AUTOSAR XML (schema 4-0-3)
standard types defined: UInt16
package /AUTOSAR_Platform/DataConstrs
  range DC_UInt16: raw 0..65535
package /PATAC/MSM/ComponentTypes
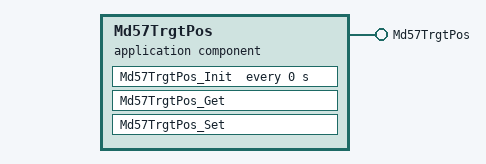
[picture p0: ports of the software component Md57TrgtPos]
  application sw component type Md57TrgtPos
    provide port Md57TrgtPos: provided-com-specs=[{operation=Get, queue-length=1}, {operation=Set, queue-length=1}], provided-interface=Md57TrgtPos
    behavior Md57TrgtPos_InternalBehavior
      operation invoked event OIT_Md57TrgtPos_Get_Md57TrgtPos_Get: start-on-event=Md57TrgtPos_Get, operation=Md57TrgtPos.Get
      timing event Md57TrgtPos_InitEvent: start-on-event=Md57TrgtPos_Init, period=0
      operation invoked event OIT_Md57TrgtPos_Set_Md57TrgtPos_Set: start-on-event=Md57TrgtPos_Set, operation=Md57TrgtPos.Set
      runnable Md57TrgtPos_Get
      runnable Md57TrgtPos_Init
      runnable Md57TrgtPos_Set
  swc implementation Md57TrgtPos_Implementation: behavior=Md57TrgtPos_InternalBehavior
    code-descriptors:
      code Default: artifact-descriptors=autosar-engineering-object={short-label=Default, category=SWSRC}
package /PATAC/MSM/ModeAdjust/PortInterface
  client server interface Md57TrgtPos
    operation Get
      5 x arg, all with type=UInt16, direction=OUT, server-argument-impl-policy=USE-ARGUMENT-TYPE:
        SecRwLtStBkReclnTrgtPos
        SecRwLtStZeroTrgtPos
        SecRwLtStLgrstUpwdDnwdTrgtPos
        SecRwLtStLgrstInwdOtwdTrgtPos
        SecRwLtStFwdBkwdTrgtPos
    operation Set
      5 x arg, all with type=UInt16, direction=IN, server-argument-impl-policy=USE-ARGUMENT-TYPE:
        SecRwLtStBkReclnTrgtPos
        SecRwLtStZeroTrgtPos
        SecRwLtStLgrstUpwdDnwdTrgtPos
        SecRwLtStLgrstInwdOtwdTrgtPos
        SecRwLtStFwdBkwdTrgtPos
